AUTOSAR XML (schema 00047)
package /EcuM/ServiceSwComponentTypes
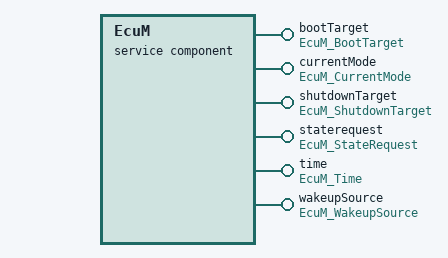
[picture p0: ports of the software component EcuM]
  service sw component type EcuM
    6 x provide port:
      bootTarget: provided-com-specs=[{operation=GetBootTarget, queue-length=1}, {operation=SelectBootTarget, queue-length=1}], provided-interface=EcuM_BootTarget
      currentMode: mode-switch-sender-com-spec{enhanced-mode-api=false, mode-group=currentMode, queue-length=1}, provided-interface=EcuM_CurrentMode
      shutdownTarget: provided-interface=EcuM_ShutdownTarget
        provided-com-specs:
          operation=GetLastShutdownTarget, queue-length=1
          operation=GetShutdownCause, queue-length=1
          operation=GetShutdownTarget, queue-length=1
          operation=GoDownHaltPoll, queue-length=1
          operation=SelectShutdownCause, queue-length=1
          operation=SelectShutdownTarget, queue-length=1
      staterequest: provided-interface=EcuM_StateRequest
        provided-com-specs:
          operation=ReleasePOST_RUN, queue-length=1
          operation=ReleaseRUN, queue-length=1
          operation=RequestOff, queue-length=1
          operation=RequestPOST_RUN, queue-length=1
          operation=RequestRUN, queue-length=1
          operation=RequestReset, queue-length=1
          operation=RequestSleep, queue-length=1
      time: provided-com-specs=[{operation=GetWakeupTime, queue-length=1}, {operation=GetCurrentTime, queue-length=1}], provided-interface=EcuM_Time
      wakeupSource: provided-interface=EcuM_WakeupSource
        provided-com-specs:
          operation=DisableWakeupSources, queue-length=1
          operation=EnableWakeupSources, queue-length=1
          operation=ClearWakeupEvent, queue-length=1
    behavior SwcIB_EcuM: data-type-mapping=EcuModeMap, handle-termination-and-restart=NO-SUPPORT
      20 x operation invoked event:
        OIE_ClearWakeupEvent: start-on-event=ClearWakeupEvent, operation=wakeupSource.ClearWakeupEvent
        OIE_DisableWakeupSources: start-on-event=DisableWakeupSources, operation=wakeupSource.DisableWakeupSources
        OIE_EnableWakeupSources: start-on-event=EnableWakeupSources, operation=wakeupSource.EnableWakeupSources
        OIE_GetBootTarget: start-on-event=GetBootTarget, operation=bootTarget.GetBootTarget
        OIE_GetCurrentTime: start-on-event=GetCurrentTime, operation=time.GetCurrentTime
        OIE_GetLastShutdownTarget: start-on-event=GetLastShutdownTarget, operation=shutdownTarget.GetLastShutdownTarget
        OIE_GetShutdownCause: start-on-event=GetShutdownCause, operation=shutdownTarget.GetShutdownCause
        OIE_GetShutdownTarget: start-on-event=GetShutdownTarget, operation=shutdownTarget.GetShutdownTarget
        OIE_GetWakeupTime: start-on-event=GetWakeupTime, operation=time.GetWakeupTime
        OIE_GoDownHaltPoll: start-on-event=GoDownHaltPoll, operation=shutdownTarget.GoDownHaltPoll
        OIE_ReleasePOST_RUN: start-on-event=ReleasePOST_RUN, operation=staterequest.ReleasePOST_RUN
        OIE_ReleaseRUN: start-on-event=ReleaseRUN, operation=staterequest.ReleaseRUN
        OIE_RequestOff: start-on-event=RequestOff, operation=staterequest.RequestOff
        OIE_RequestPOST_RUN: start-on-event=RequestPOST_RUN, operation=staterequest.RequestPOST_RUN
        OIE_RequestRUN: start-on-event=RequestRUN, operation=staterequest.RequestRUN
        OIE_RequestReset: start-on-event=RequestReset, operation=staterequest.RequestReset
        OIE_RequestSleep: start-on-event=RequestSleep, operation=staterequest.RequestSleep
        OIE_SelectBootTarget: start-on-event=SelectBootTarget, operation=bootTarget.SelectBootTarget
        OIE_SelectShutdownCause: start-on-event=SelectShutdownCause, operation=shutdownTarget.SelectShutdownCause
        OIE_SelectShutdownTarget: start-on-event=SelectShutdownTarget, operation=shutdownTarget.SelectShutdownTarget
      21 x runnable, all with can-be-invoked-concurrently=true:
        ClearWakeupEvent: symbol=EcuM_ClearWakeupEvent
        DisableWakeupSources: symbol=EcuM_DisableWakeupSources
        EnableWakeupSources: symbol=EcuM_EnableWakeupSources
        GetBootTarget: symbol=EcuM_GetBootTarget
        GetCurrentTime: symbol=EcuM_GetCurrentTime
        GetLastShutdownTarget: symbol=EcuM_GetLastShutdownTarget
        GetShutdownCause: symbol=EcuM_GetShutdownCause
        GetShutdownTarget: symbol=EcuM_GetShutdownTarget
        GetWakeupTime: symbol=EcuM_GetWakeupTime
        GoDownHaltPoll: symbol=EcuM_GoDownHaltPoll
        ReleasePOST_RUN: symbol=EcuM_ReleasePOST_RUN
        ReleaseRUN: symbol=EcuM_ReleaseRUN
        RequestOff: symbol=EcuM_RequestOff
        RequestPOST_RUN: symbol=EcuM_RequestPOST_RUN
        RequestRUN: symbol=EcuM_RequestRUN
        RequestReset: symbol=EcuM_RequestReset
        RequestSleep: symbol=EcuM_RequestSleep
        Rte_Switch_currentMode_currentMode
          mode switch point MSP_Rte_Switch_currentMode_currentMode: mode-group=currentMode.currentMode
        SelectBootTarget: symbol=EcuM_SelectBootTarget
        SelectShutdownCause: symbol=EcuM_SelectShutdownCause
        SelectShutdownTarget: symbol=EcuM_SelectShutdownTarget
  swc bsw mapping SwcBswMapping_EcuM: bsw-behavior=BswIB_EcuM, swc-behavior=SwcIB_EcuM
  swc implementation SwcImplementation_EcuM: programming-language=C, swc-bsw-mapping=SwcBswMapping_EcuM, behavior=SwcIB_EcuM
